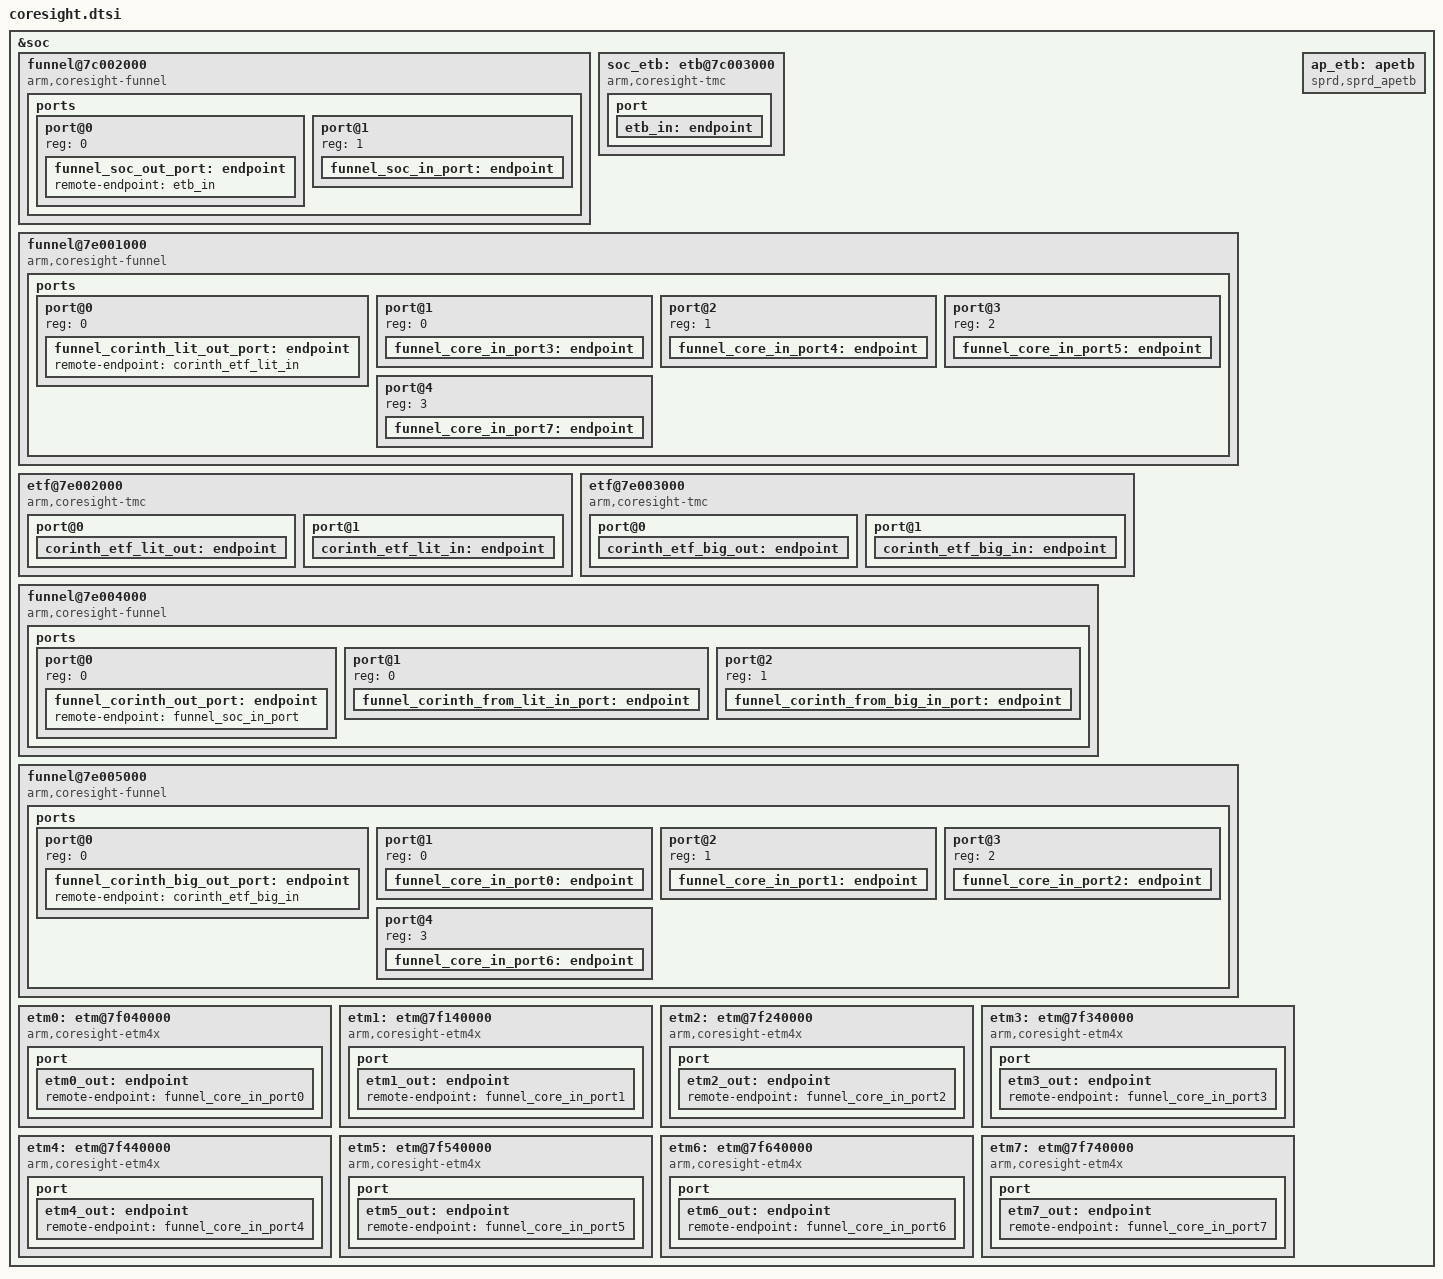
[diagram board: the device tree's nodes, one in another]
// SPDX-License-Identifier: (GPL-2.0+ OR MIT)
/*
 * Copyright (C) 2020, Unisoc Inc.
 */

&soc {
	/*    etm
	 * -> apcpu_funnel lit/big
	 * -> apcpu_etf lit/big
	 * -> funnel_to_soc
	 * -> soc_funnel
	 * -> soc_etf
	 */

	/* soc_funnel */
	funnel@7c002000 {
		compatible = "arm,coresight-funnel", "arm,primecell";
		reg = <0 0x7c002000 0 0x1000>;
		clocks = <&ext_26m>;
		clock-names = "apb_pclk";
		ports {
			#address-cells = <1>;
			#size-cells = <0>;

			port@0 {
				reg = <0>;
				funnel_soc_out_port: endpoint {
					remote-endpoint = <&etb_in>;
				};
			};

			port@1 {
				reg = <1>;
				funnel_soc_in_port: endpoint {
					slave-mode;
					remote-endpoint = <&funnel_corinth_out_port>;
				};
			};
		};
	};
	/* soc_etf */
	soc_etb: etb@7c003000 {
		compatible = "arm,coresight-tmc", "arm,primecell";
		reg = <0 0x7c003000 0 0x1000>;
		clocks = <&ext_26m>;
		clock-names = "apb_pclk";
		port {
			etb_in: endpoint {
				slave-mode;
				remote-endpoint = <&funnel_soc_out_port>;
			};
		};
	};

	/* apcpu funnel lit core3/4/5/7 */
	funnel@7e001000 {
		compatible = "arm,coresight-funnel", "arm,primecell";
		reg = <0 0x7e001000 0 0x1000>;
		clocks = <&ext_26m>;
		clock-names = "apb_pclk";

		ports {
			#address-cells = <1>;
			#size-cells = <0>;

			port@0 {
				reg = <0>;
				funnel_corinth_lit_out_port: endpoint {
					remote-endpoint = <&corinth_etf_lit_in>;
				};
			};

			port@1 {
				reg = <0>;
				funnel_core_in_port3: endpoint {
					slave-mode;
					remote-endpoint = <&etm3_out>;
				};
			};

			port@2 {
				reg = <1>;
				funnel_core_in_port4: endpoint {
					slave-mode;
					remote-endpoint = <&etm4_out>;
				};
			};

			port@3 {
				reg = <2>;
				funnel_core_in_port5: endpoint {
					slave-mode;
					remote-endpoint = <&etm5_out>;
				};
			};

			port@4 {
				reg = <3>;
				funnel_core_in_port7: endpoint {
					slave-mode;
					remote-endpoint = <&etm7_out>;
				};
			};
		};
	};

	/* apcpu lit etf */
	etf@7e002000 {
		compatible = "arm,coresight-tmc", "arm,primecell";
		reg = <0 0x7e002000 0 0x1000>;
		clocks = <&ext_26m>;
		clock-names = "apb_pclk";

		port@0 {
			corinth_etf_lit_out: endpoint {
				remote-endpoint = <&funnel_corinth_from_lit_in_port>;
			};
		};

		port@1 {
			corinth_etf_lit_in: endpoint {
				slave-mode;
				remote-endpoint = <&funnel_corinth_lit_out_port>;
			};
		};
	};

	/* apcpu big etf */
	etf@7e003000 {
		compatible = "arm,coresight-tmc", "arm,primecell";
		reg = <0 0x7e003000 0 0x1000>;
		clocks = <&ext_26m>;
		clock-names = "apb_pclk";

		port@0 {
			corinth_etf_big_out: endpoint {
				remote-endpoint = <&funnel_corinth_from_big_in_port>;
			};
		};

		port@1 {
			corinth_etf_big_in: endpoint {
				slave-mode;
				remote-endpoint = <&funnel_corinth_big_out_port>;
			};
		};
	};

	/* funnel to Soc */
	funnel@7e004000 {
		compatible = "arm,coresight-funnel", "arm,primecell";
		reg = <0 0x7e004000 0 0x1000>;
		clocks = <&ext_26m>;
		clock-names = "apb_pclk";
		ports {
			#address-cells = <1>;
			#size-cells = <0>;

			port@0 {
				reg = <0>;
				funnel_corinth_out_port: endpoint {
					remote-endpoint = <&funnel_soc_in_port>;
				};
			};

			port@1 {
				reg = <0>;
				funnel_corinth_from_lit_in_port: endpoint {
					slave-mode;
					remote-endpoint = <&corinth_etf_lit_out>;
				};
			};

			port@2 {
				reg = <1>;
				funnel_corinth_from_big_in_port: endpoint {
					slave-mode;
					remote-endpoint = <&corinth_etf_big_out>;
				};
			};
		};
	};

	/* apcpu funnel big core0/1/2/6 */
	funnel@7e005000 {
		compatible = "arm,coresight-funnel", "arm,primecell";
		reg = <0 0x7e005000 0 0x1000>;
		clocks = <&ext_26m>;
		clock-names = "apb_pclk";

		ports {
			#address-cells = <1>;
			#size-cells = <0>;

			port@0 {
				reg = <0>;
				funnel_corinth_big_out_port: endpoint {
					remote-endpoint = <&corinth_etf_big_in>;
				};
			};

			port@1 {
				reg = <0>;
				funnel_core_in_port0: endpoint {
					slave-mode;
					remote-endpoint = <&etm0_out>;
				};
			};

			port@2 {
				reg = <1>;
				funnel_core_in_port1: endpoint {
					slave-mode;
					remote-endpoint = <&etm1_out>;
				};
			};

			port@3 {
				reg = <2>;
				funnel_core_in_port2: endpoint {
					slave-mode;
					remote-endpoint = <&etm2_out>;
				};
			};

			port@4 {
				reg = <3>;
				funnel_core_in_port6: endpoint {
					slave-mode;
					remote-endpoint = <&etm6_out>;
				};
			};
		};
	};

	etm0: etm@7f040000 {
		compatible = "arm,coresight-etm4x", "arm,primecell";
		reg = <0 0x7f040000 0 0x1000>;
		cpu = <&CPU0>;
		clocks = <&ext_26m>, <&aon_clk CLK_CSSYS>, <&pll1 CLK_TWPLL_256M>;
		clock-names = "apb_pclk", "clk_cs", "cs_src";

		port {
			etm0_out: endpoint {
				remote-endpoint = <&funnel_core_in_port0>;
			};
		};
	};

	etm1: etm@7f140000 {
		compatible = "arm,coresight-etm4x", "arm,primecell";
		reg = <0 0x7f140000 0 0x1000>;
		cpu = <&CPU1>;
		clocks = <&ext_26m>, <&aon_clk CLK_CSSYS>, <&pll1 CLK_TWPLL_256M>;
		clock-names = "apb_pclk", "clk_cs", "cs_src";

		port {
			etm1_out: endpoint {
				remote-endpoint = <&funnel_core_in_port1>;
			};
		};
	};

	etm2: etm@7f240000 {
		compatible = "arm,coresight-etm4x", "arm,primecell";
		reg = <0 0x7f240000 0 0x1000>;
		cpu = <&CPU2>;
		clocks = <&ext_26m>, <&aon_clk CLK_CSSYS>, <&pll1 CLK_TWPLL_256M>;
		clock-names = "apb_pclk", "clk_cs", "cs_src";

		port {
			etm2_out: endpoint {
				remote-endpoint = <&funnel_core_in_port2>;
			};
		};
	};

	etm3: etm@7f340000 {
		compatible = "arm,coresight-etm4x", "arm,primecell";
		reg = <0 0x7f340000 0 0x1000>;
		cpu = <&CPU3>;
		clocks = <&ext_26m>, <&aon_clk CLK_CSSYS>, <&pll1 CLK_TWPLL_256M>;
		clock-names = "apb_pclk", "clk_cs", "cs_src";

		port {
			etm3_out: endpoint {
				remote-endpoint = <&funnel_core_in_port3>;
			};
		};
	};

	etm4: etm@7f440000 {
		compatible = "arm,coresight-etm4x", "arm,primecell";
		reg = <0 0x7f440000 0 0x1000>;
		cpu = <&CPU4>;
		clocks = <&ext_26m>, <&aon_clk CLK_CSSYS>, <&pll1 CLK_TWPLL_256M>;
		clock-names = "apb_pclk", "clk_cs", "cs_src";

		port {
			etm4_out: endpoint {
				remote-endpoint = <&funnel_core_in_port4>;
			};
		};
	};

	etm5: etm@7f540000 {
		compatible = "arm,coresight-etm4x", "arm,primecell";
		reg = <0 0x7f540000 0 0x1000>;
		cpu = <&CPU5>;
		clocks = <&ext_26m>, <&aon_clk CLK_CSSYS>, <&pll1 CLK_TWPLL_256M>;
		clock-names = "apb_pclk", "clk_cs", "cs_src";

		port {
			etm5_out: endpoint {
				remote-endpoint = <&funnel_core_in_port5>;
			};
		};
	};

	etm6: etm@7f640000 {
		compatible = "arm,coresight-etm4x", "arm,primecell";
		reg = <0 0x7f640000 0 0x1000>;
		cpu = <&CPU6>;
		clocks = <&ext_26m>, <&aon_clk CLK_CSSYS>, <&pll1 CLK_TWPLL_256M>;
		clock-names = "apb_pclk", "clk_cs", "cs_src";

		port {
			etm6_out: endpoint {
				remote-endpoint = <&funnel_core_in_port6>;
			};
		};
	};

	etm7: etm@7f740000 {
		compatible = "arm,coresight-etm4x", "arm,primecell";
		reg = <0 0x7f740000 0 0x1000>;
		cpu = <&CPU7>;
		clocks = <&ext_26m>, <&aon_clk CLK_CSSYS>, <&pll1 CLK_TWPLL_256M>;
		clock-names = "apb_pclk", "clk_cs", "cs_src";

		port {
			etm7_out: endpoint {
				remote-endpoint = <&funnel_core_in_port7>;
			};
		};
	};

	ap_etb: apetb {
		compatible = "sprd,sprd_apetb";
		apetb-source = <&etm0 &etm1 &etm2 &etm3 &etm4 &etm5 &etm6 &etm7>;
		apetb-sink = <&soc_etb>;
	};
};
